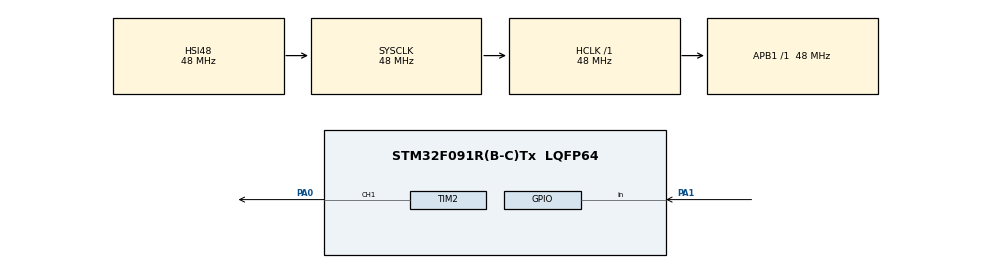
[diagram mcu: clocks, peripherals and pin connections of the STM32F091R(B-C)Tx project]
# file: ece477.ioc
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Mcu.Family=STM32F0
Mcu.Name=STM32F091R(B-C)Tx
Mcu.Package=LQFP64
PA0.Signal=S_TIM2_CH1_ETR
PA1.Signal=GPIO_Input
PA13.Mode=Serial_Wire
PA13.Signal=SYS_SWDIO
PA14.Mode=Serial_Wire
PA14.Signal=SYS_SWCLK
PF0-OSC_IN.Mode=HSE-External-Oscillator
PF0-OSC_IN.Signal=RCC_OSC_IN
PF1-OSC_OUT.Mode=HSE-External-Oscillator
PF1-OSC_OUT.Signal=RCC_OSC_OUT
ProjectManager.HeapSize=0x200
ProjectManager.StackSize=0x400
ProjectManager.TargetToolchain=STM32CubeIDE
RCC.AHBFreq_Value=48000000
RCC.APB1Freq_Value=48000000
RCC.APB1TimFreq_Value=48000000
RCC.HCLKFreq_Value=48000000
RCC.SYSCLKFreq_VALUE=48000000
RCC.SYSCLKSource=RCC_SYSCLKSOURCE_HSI48
SH.S_TIM2_CH1_ETR.0=TIM2_CH1,PWM Generation1 CH1
TIM2.AutoReloadPreload=TIM_AUTORELOAD_PRELOAD_ENABLE
TIM2.Channel-PWM\ Generation1\ CH1=TIM_CHANNEL_1
TIM2.Period=65535
VP_TIM2_VS_ClockSourceINT.Mode=Internal
board=custom

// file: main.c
/* USER CODE BEGIN Header */
/**
  ******************************************************************************
  * @file           : main.c
  * @brief          : Main program body
  ******************************************************************************
  * @attention
  *
  * Copyright (c) 2023 STMicroelectronics.
  * All rights reserved.
  *
  * This software is licensed under terms that can be found in the LICENSE file
  * in the root directory of this software component.
  * If no LICENSE file comes with this software, it is provided AS-IS.
  *
  ******************************************************************************
  */
/* USER CODE END Header */
#include "main.h"
#define BUTTON_PIN (1);

TIM_HandleTypeDef htim2;

void SystemClock_Config(void);
static void MX_GPIO_Init(void);
static void MX_TIM2_Init(void);

int main(void)
{

  /* MCU Configuration--------------------------------------------------------*/

  /* Reset of all peripherals, Initializes the Flash interface and the Systick. */
  HAL_Init();

  /* Configure the system clock */
  SystemClock_Config();

  /* Initialize all configured peripherals */
  MX_GPIO_Init();
  MX_TIM2_Init();

  /* Infinite loop */
  /* USER CODE BEGIN WHILE */
  while(1) {
      while(HAL_GPIO_ReadPin(GPIOA, GPIO_PIN_1)){
            HAL_TIM_PWM_Start(&htim2, TIM_CHANNEL_1);
          /* USER CODE END WHILE */
                //PWM 80% Duty Cycle
            TIM2->ARR = 9600000-1;
            TIM2->CCR1 = 7700000;
        }

        HAL_TIM_PWM_Stop(&htim2, TIM_CHANNEL_1);
  }
}

void SystemClock_Config(void)
{
  RCC_OscInitTypeDef RCC_OscInitStruct = {0};
  RCC_ClkInitTypeDef RCC_ClkInitStruct = {0};

  /** Initializes the RCC Oscillators according to the specified parameters
  * in the RCC_OscInitTypeDef structure.
  */
  RCC_OscInitStruct.OscillatorType = RCC_OSCILLATORTYPE_HSI48;
  RCC_OscInitStruct.HSI48State = RCC_HSI48_ON;
  RCC_OscInitStruct.PLL.PLLState = RCC_PLL_NONE;
  if (HAL_RCC_OscConfig(&RCC_OscInitStruct) != HAL_OK)
  {
    Error_Handler();
  }

  /** Initializes the CPU, AHB and APB buses clocks
  */
  RCC_ClkInitStruct.ClockType = RCC_CLOCKTYPE_HCLK|RCC_CLOCKTYPE_SYSCLK
                              |RCC_CLOCKTYPE_PCLK1;
  RCC_ClkInitStruct.SYSCLKSource = RCC_SYSCLKSOURCE_HSI48;
  RCC_ClkInitStruct.AHBCLKDivider = RCC_SYSCLK_DIV1;
  RCC_ClkInitStruct.APB1CLKDivider = RCC_HCLK_DIV1;

  if (HAL_RCC_ClockConfig(&RCC_ClkInitStruct, FLASH_LATENCY_1) != HAL_OK)
  {
    Error_Handler();
  }
}

static void MX_TIM2_Init(void)
{

  TIM_ClockConfigTypeDef sClockSourceConfig = {0};
  TIM_MasterConfigTypeDef sMasterConfig = {0};
  TIM_OC_InitTypeDef sConfigOC = {0};

  htim2.Instance = TIM2;
  htim2.Init.Prescaler = 0;
  htim2.Init.CounterMode = TIM_COUNTERMODE_UP;
  htim2.Init.Period = 65535;
  htim2.Init.ClockDivision = TIM_CLOCKDIVISION_DIV1;
  htim2.Init.AutoReloadPreload = TIM_AUTORELOAD_PRELOAD_ENABLE;
  if (HAL_TIM_Base_Init(&htim2) != HAL_OK)
  {
    Error_Handler();
  }
  sClockSourceConfig.ClockSource = TIM_CLOCKSOURCE_INTERNAL;
  if (HAL_TIM_ConfigClockSource(&htim2, &sClockSourceConfig) != HAL_OK)
  {
    Error_Handler();
  }
  if (HAL_TIM_PWM_Init(&htim2) != HAL_OK)
  {
    Error_Handler();
  }
  sMasterConfig.MasterOutputTrigger = TIM_TRGO_RESET;
  sMasterConfig.MasterSlaveMode = TIM_MASTERSLAVEMODE_DISABLE;
  if (HAL_TIMEx_MasterConfigSynchronization(&htim2, &sMasterConfig) != HAL_OK)
  {
    Error_Handler();
  }
  sConfigOC.OCMode = TIM_OCMODE_PWM1;
  sConfigOC.Pulse = 0;
  sConfigOC.OCPolarity = TIM_OCPOLARITY_HIGH;
  sConfigOC.OCFastMode = TIM_OCFAST_DISABLE;
  if (HAL_TIM_PWM_ConfigChannel(&htim2, &sConfigOC, TIM_CHANNEL_1) != HAL_OK)
  {
    Error_Handler();
  }
  HAL_TIM_MspPostInit(&htim2);

}

static void MX_GPIO_Init(void)
{
  GPIO_InitTypeDef GPIO_InitStruct = {0};

  /* GPIO Ports Clock Enable */
  __HAL_RCC_GPIOF_CLK_ENABLE();
  __HAL_RCC_GPIOA_CLK_ENABLE();

  /*Configure GPIO pin : PA1 */
  GPIO_InitStruct.Pin = GPIO_PIN_1;
  GPIO_InitStruct.Mode = GPIO_MODE_INPUT;
  GPIO_InitStruct.Pull = GPIO_NOPULL;
  HAL_GPIO_Init(GPIOA, &GPIO_InitStruct);

}

void Error_Handler(void)
{
}
